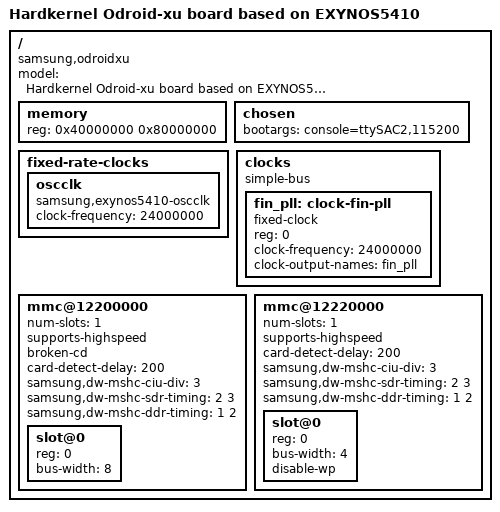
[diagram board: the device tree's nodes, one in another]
/*
 * Hardkernel's Odroid-xu board device tree source
 *
 * Copyright (c) 2013 Hardkernel Co., Ltd.
 *		http://www.hardkernel.com
 *
 * This program is free software; you can redistribute it and/or modify
 * it under the terms of the GNU General Public License version 2 as
 * published by the Free Software Foundation.
*/

/dts-v1/;
#include <dt-bindings/clock/exynos5410.h>
#include "exynos5410.dtsi"
/ {
	model = "Hardkernel Odroid-xu board based on EXYNOS5410";
	compatible = "samsung,odroidxu", "samsung,exynos5410";

	memory {
		reg = <0x40000000 0x80000000>;
	};

	chosen {
		bootargs = "console=ttySAC2,115200";
	};

	fixed-rate-clocks {
		oscclk {
			compatible = "samsung,exynos5410-oscclk";
			clock-frequency = <24000000>;
        };
    };

    clocks {
        compatible = "simple-bus";
        #address-cells = <1>;
        #size-cells = <0>;

        fin_pll: clock-fin-pll {
            compatible = "fixed-clock";
            reg = <0>;
            #clock-cells = <0>;
            clock-frequency = <24000000>;
            clock-output-names = "fin_pll";
        };
    };

	mmc@12200000 {
		status = "okay";
		num-slots = <1>;
		supports-highspeed;
		broken-cd;
		card-detect-delay = <200>;
		samsung,dw-mshc-ciu-div = <3>;
		samsung,dw-mshc-sdr-timing = <2 3>;
		samsung,dw-mshc-ddr-timing = <1 2>;

		slot@0 {
			reg = <0>;
			bus-width = <8>;
		};
	};

	mmc@12220000 {
		status = "okay";
		num-slots = <1>;
		supports-highspeed;
		card-detect-delay = <200>;
		samsung,dw-mshc-ciu-div = <3>;
		samsung,dw-mshc-sdr-timing = <2 3>;
		samsung,dw-mshc-ddr-timing = <1 2>;

		slot@0 {
			reg = <0>;
			bus-width = <4>;
			disable-wp;
		};
	};

};
